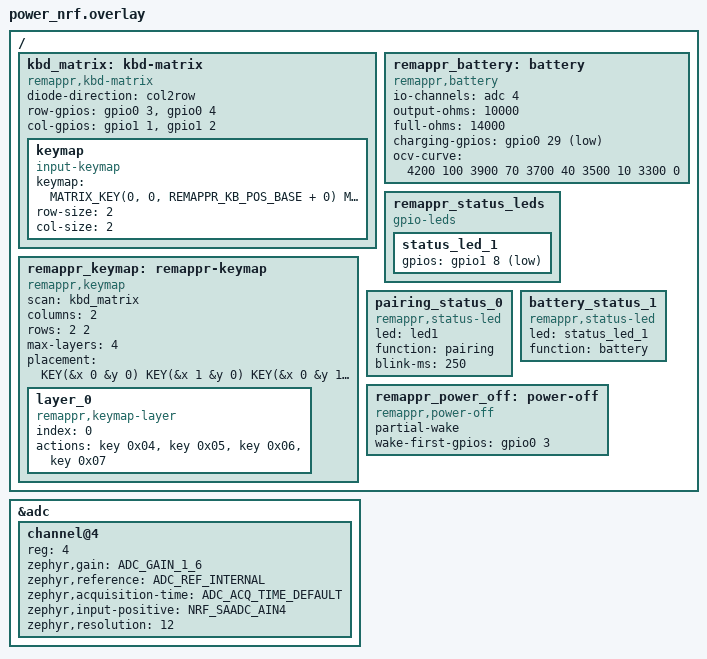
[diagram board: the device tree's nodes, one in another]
/*
 * Power nRF — Remappr shield (generated by remappr).
 *
 * Drop this directory into a remappr-firmware checkout under
 * boards/shields/power_nrf/ and build with -Dremappr_SHIELD=power_nrf. Verify the
 * row/col GPIO specs against your wiring — remappr derives the matrix
 * cells from physical key position, not the electrical matrix.
 *
 * SPDX-License-Identifier: Apache-2.0
 */

#include <zephyr/dt-bindings/input/input-event-codes.h>
#include <zephyr/dt-bindings/input/keymap.h>
#include <dt-bindings/remappr/keys.h>
#include <dt-bindings/remappr/layout.h>
#include <remappr/keymap-tokens.dtsi>
#include <remappr/behavior-tokens.dtsi>
#include <zephyr/dt-bindings/adc/adc.h>
#include <zephyr/dt-bindings/adc/nrf-saadc.h>

/ {
	kbd_matrix: kbd-matrix {
		compatible = "remappr,kbd-matrix";
		diode-direction = "col2row";
		row-gpios =
			<&gpio0 3 (GPIO_ACTIVE_HIGH | GPIO_PULL_DOWN)>,
			<&gpio0 4 (GPIO_ACTIVE_HIGH | GPIO_PULL_DOWN)>;
		col-gpios =
			<&gpio1 1 GPIO_ACTIVE_HIGH>,
			<&gpio1 2 GPIO_ACTIVE_HIGH>;

		keymap {
			compatible = "input-keymap";
			keymap = <
				MATRIX_KEY(0, 0, REMAPPR_KB_POS_BASE + 0) MATRIX_KEY(0, 1, REMAPPR_KB_POS_BASE + 1)
				MATRIX_KEY(1, 0, REMAPPR_KB_POS_BASE + 2) MATRIX_KEY(1, 1, REMAPPR_KB_POS_BASE + 3)
			>;
			row-size = <2>;
			col-size = <2>;
		};
	};

	remappr_keymap: remappr-keymap {
		compatible = "remappr,keymap";
		scan = <&kbd_matrix>;
		columns = <2>;
		rows = <2 2>;
		max-layers = <4>;
		placement = <
				KEY(&x 0 &y 0) KEY(&x 1 &y 0)
				KEY(&x 0 &y 1) KEY(&x 1 &y 1)
		>;
		layer_0 {
			compatible = "remappr,keymap-layer";
			index = <0>;
			actions = <
				&key 0x04 &key 0x05
				&key 0x06 &key 0x07
			>;
		};
	};
};

/ {
	remappr_battery: battery {
		compatible = "remappr,battery";
		io-channels = <&adc 4>;
		output-ohms = <10000>;
		full-ohms = <14000>;
		charging-gpios = <&gpio0 29 (GPIO_PULL_UP | GPIO_ACTIVE_LOW)>;
		ocv-curve = <
			4200 100
			3900 70
			3700 40
			3500 10
			3300 0
		>;
	};
};

/ {
	remappr_status_leds {
		compatible = "gpio-leds";
		status_led_1: status_led_1 {
			gpios = <&gpio1 8 GPIO_ACTIVE_LOW>;
		};
	};

	pairing_status_0 {
		compatible = "remappr,status-led";
		led = <&led1>;
		function = "pairing";
		blink-ms = <250>;
	};
	battery_status_1 {
		compatible = "remappr,status-led";
		led = <&status_led_1>;
		function = "battery";
	};
};

/ {
	remappr_power_off: power-off {
		compatible = "remappr,power-off";
		partial-wake;
		wake-first-gpios = <&gpio0 3 0>;
	};
};

&adc {
	status = "okay";
	#address-cells = <1>;
	#size-cells = <0>;

	channel@4 {
		reg = <4>;
		zephyr,gain = "ADC_GAIN_1_6";
		zephyr,reference = "ADC_REF_INTERNAL";
		zephyr,acquisition-time = <ADC_ACQ_TIME_DEFAULT>;
		zephyr,input-positive = <NRF_SAADC_AIN4>;
		zephyr,resolution = <12>;
	};
};
